# UHH_CONFIG register map
Vendor: Texas Instruments
Peripheral module from a debugger description file (folder omap5430_ES2_PUBLIC).
Registers are 32-bit, read-write, reset values left out (the file's numbers can be read two ways) unless marked. A register's access mark holds for its fields unless they carry their own. Offsets are as the file gives them; lines under a group give offsets from that group; [hi:lo] are bit positions; {n}, {i} and the like mark numbered series; 'fields as' and 'values as' point back to an identical list; <NAME> marks a mode.

## UHH_CONFIG
0x00 UHH_REVISION ro — USB high-speed host (UHH) revision identifier (X.Y.R) Used by software to track features, bugs, and compatibility
  [31:0] REVISION — IP revision
0x04 UHH_HWINFO ro — Information on host hardware configuration
  [9:0] SAR_CNTX_SIZE — Save-and-restore context size, in 32-bit words; that is, number of 32-bit registers with significant context information, mapped from offset 0x100 upward.
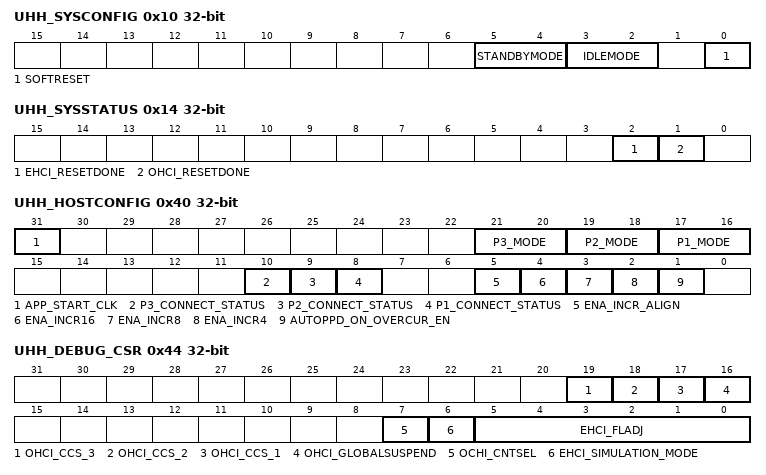
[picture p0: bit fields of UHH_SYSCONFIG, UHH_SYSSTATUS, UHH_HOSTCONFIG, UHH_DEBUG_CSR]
0x10 UHH_SYSCONFIG access per field — OCP standard system configuration register
  [5:4] STANDBYMODE rw — Mstandby/Mwait/[Mwakeup] initiator power-management interface configuration
    0=Force-standby mode. Mstandby asserted unconditionally. Asynchronous (master) wake-up disabled.; 1=No-standby mode. Mstandby never asserted. Asynchronous (master) wakeup disabled.; 2=Smart-standby mode. Mstandby asserted when initiator activity stops. Asynchronous (master) wake-up disabled.; 3=smartstandby_wakeup (USBHOST doesn't support Smart standby + wakeup feature. Hence this is always disabled and software programming to this mode would result in undesired behaviour.)
  [3:2] IDLEMODE rw — Sidlereq/Sidleack(1:0)/[Swakeup] target power management interface configuration.
    0=Force-Idle mode. Sidleack asserted after Idlereq assertion. Asynchronous (slave) wake-up disabled.; 1=No-idle mode. Sidleack never asserted. Asynchronous (slave) wakeup disabled.; 2=Smart-idle mode. Sidleack asserted upon Idlereq assertion, after target activity is over. Asynchronous (slave) wake-up disabled.; 3=Smart-idle wake-up mode. Like smart mode with asynchronous (slave) wakeup enabled.
  [0] SOFTRESET rw — Module software reset
    0=nothing_pending (No reset pending); 0=nothing_pending (No effect); 1=reset_pending (Starts softreset sequence.); 1=reset_pending (Reset (soft or other) is pending.)
0x14 UHH_SYSSTATUS ro — Module-specific system status
  [2] EHCI_RESETDONE — Indicates when the EHCI HS host is out of reset
    0=reset (Out of reset); 1=reset (Under reset)
  [1] OHCI_RESETDONE — Indicates when the OHCI FS/LS host is out of reset
    0=reset (Out of reset); 1=reset (Under reset)
0x40 UHH_HOSTCONFIG access per field — Static configuration of the USB HS host
  [31] APP_START_CLK rw — When the OHCI clocks are suspended, the system has to assert this signal to start the clocks (12 and 48 MHz). This should be de-asserted after the clocks are started and before the host is suspended again. (Host is suspended means HCFS = SUSPEND or all the OHCI ports are suspended).
  [21:20] P3_MODE rw — Port 3 interface configuration. Each bit corresponds to an internal 'strap' signal, and output: Bit 0 = ulpi_bypass Bit 1 = hsic_en
    0=ulpi (To external ULPI PHY, HS only); 1=utmi (To UTMI PHY (or ULPI TLL), FS/LS capable); 3=hsic (To HSIC digital front-end (DFE), HS only); 2=forbidden
  [19:18] P2_MODE rw — Port 2 interface configuration. Each bit corresponds to an internal 'strap' signal, and output: Bit 0 = ulpi_bypass Bit 1 = hsic_en
    values as P3_MODE
  [17:16] P1_MODE rw — Port 1 interface configuration. Each bit corresponds to an internal 'strap' signal, and output: Bit 0 = ulpi_bypass Bit 1 = hsic_en
    values as P3_MODE
  [10] P3_CONNECT_STATUS ro — Connection status for port 3
    1=con (Peripheral connected and active on port); 0=Disconnected
  [9] P2_CONNECT_STATUS ro — Connection status for port 2
    values as P3_CONNECT_STATUS
  [8] P1_CONNECT_STATUS ro — Connection status for port 1
    values as P3_CONNECT_STATUS
  [5] ENA_INCR_ALIGN rw — Force alignment of bursts to the respective burst-size boundaries. This bit must be set to 1 to avoid buffer underflow.
    0=dis (disable burst type); 1=en (enable burst type)
  [4] ENA_INCR16 rw — Control the use of INCR16-type bursts (in AHB sense)
    0=dis (disable burst type); 1=en (enable burst type)
  [3] ENA_INCR8 rw — Control the use of INCR8-type bursts (in AHB sense)
    0=dis (disable burst type); 1=en (enable burst type)
  [2] ENA_INCR4 rw — Control the use of INCR4-type bursts (in AHB sense)
    0=dis (disable burst type); 1=en (enable burst type)
  [1] AUTOPPD_ON_OVERCUR_EN rw — Configure reaction upon port overcurrent condition
    0=dis (Port remains on upon overcurrent); 1=en (Port is powered down automatically upon overcurrent)
0x44 UHH_DEBUG_CSR access per field — Debug control and status for the EHCI, OHCI hosts
  [19] OHCI_CCS_3 ro — Current Connect Status of port 3
    1=connected (periph connected); 0=disconnected (no periph connected)
  [18] OHCI_CCS_2 ro — Current Connect Status of port 2
    values as OHCI_CCS_3
  [17] OHCI_CCS_1 ro — Current Connect Status of port 1
    values as OHCI_CCS_3
  [16] OHCI_GLOBALSUSPEND ro — OHCI global suspend status, asserted 5ms after the suspend order.
    1=suspended (host is suspended); 0=active (host is not suspended)
  [7] OCHI_CNTSEL rw — Selection of a shorter '1 ms' counter in OHCI host, to speed up long USB phases like reset, resume, etc... (Used only for simulation.)
    0=noaction (functional mode, 1ms = 12,000 x 12 MHz cycles); 1=speedup (simulation mode, 1ms = 7 x 12 MHz cycles = 583 ns)
  [6] EHCI_SIMULATION_MODE rw — Sets the PHY to non-driving mode. (Used only for simulation.)
    0=noaction (functional mode); 1=phy_nodrive (PHY set to non-driving)
  [5:0] EHCI_FLADJ rw — EHCI host frame length adjust. Modify only when EHCI bitfieldUSBSTS.HCHalted = 1 Field value + 59,488 = 60,000 by default = number of 60 MHz UTMI/ULPI clock cycles per 1 ms USB frame = number of 480 MHz HS bits per 125 us HS USB microframe
{0x100+4i} UHH_SAR_CNTX_i_{i} (i=0..383) — Save and restore context array. Array size is indicated in. When in SAR mode, read out to save and write to restore. Do not access when not in SAR mode.
  [31:0] CNTX — Context bits
